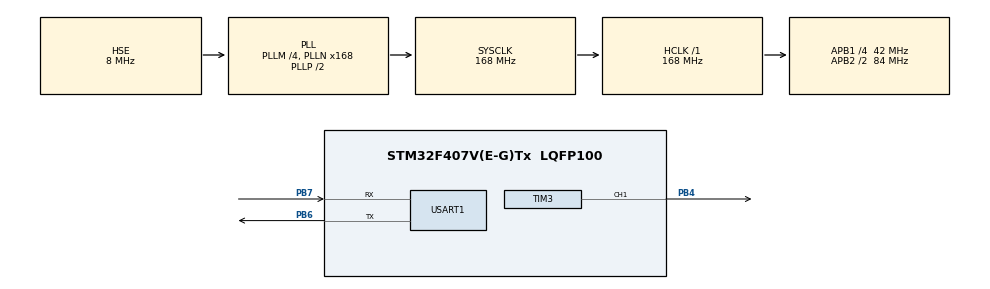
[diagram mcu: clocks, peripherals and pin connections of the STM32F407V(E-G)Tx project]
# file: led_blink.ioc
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FREERTOS.Tasks01=defaultTask,24,128,StartDefaultTask,Default,NULL,Dynamic,NULL,NULL
Mcu.Family=STM32F4
Mcu.Name=STM32F407V(E-G)Tx
Mcu.Package=LQFP100
NVIC.PriorityGroup=NVIC_PRIORITYGROUP_4
NVIC.TIM1_UP_TIM10_IRQn=true\:0\:0\:false\:false\:true\:false\:false\:true
NVIC.TimeBase=TIM1_UP_TIM10_IRQn
NVIC.TimeBaseIP=TIM1
NVIC.USART1_IRQn=true\:5\:0\:false\:false\:true\:true\:true\:true
PA13.Mode=Serial_Wire
PA13.Signal=SYS_JTMS-SWDIO
PA14.Mode=Serial_Wire
PA14.Signal=SYS_JTCK-SWCLK
PB4.Signal=S_TIM3_CH1
PB6.Mode=Asynchronous
PB6.Signal=USART1_TX
PB7.Mode=Asynchronous
PB7.Signal=USART1_RX
PH0-OSC_IN.Mode=HSE-External-Oscillator
PH0-OSC_IN.Signal=RCC_OSC_IN
PH1-OSC_OUT.Mode=HSE-External-Oscillator
PH1-OSC_OUT.Signal=RCC_OSC_OUT
ProjectManager.HeapSize=0x200
ProjectManager.StackSize=0x400
ProjectManager.TargetToolchain=MDK-ARM V5.27
RCC.48MHZClocksFreq_Value=84000000
RCC.AHBFreq_Value=168000000
RCC.APB1CLKDivider=RCC_HCLK_DIV4
RCC.APB1Freq_Value=42000000
RCC.APB1TimFreq_Value=84000000
RCC.APB2CLKDivider=RCC_HCLK_DIV2
RCC.APB2Freq_Value=84000000
RCC.APB2TimFreq_Value=168000000
RCC.CortexFreq_Value=168000000
RCC.HCLKFreq_Value=168000000
RCC.HSE_VALUE=8000000
RCC.HSI_VALUE=16000000
RCC.LSE_VALUE=32768
RCC.PLLM=4
RCC.PLLN=168
RCC.PLLSourceVirtual=RCC_PLLSOURCE_HSE
RCC.SYSCLKFreq_VALUE=168000000
RCC.SYSCLKSource=RCC_SYSCLKSOURCE_PLLCLK
RCC.VCOOutputFreq_Value=336000000
SH.S_TIM3_CH1.0=TIM3_CH1,PWM Generation1 CH1
TIM3.AutoReloadPreload=TIM_AUTORELOAD_PRELOAD_ENABLE
TIM3.Channel-PWM\ Generation1\ CH1=TIM_CHANNEL_1
TIM3.OCMode_PWM-PWM\ Generation1\ CH1=TIM_OCMODE_PWM1
TIM3.Period=999
TIM3.Prescaler=83
USART1.VirtualMode=VM_ASYNC
VP_FREERTOS_VS_CMSIS_V2.Mode=CMSIS_V2
VP_SYS_VS_tim1.Mode=TIM1
VP_TIM3_VS_ClockSourceINT.Mode=Internal
board=custom

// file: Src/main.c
/* USER CODE BEGIN Header */
/**
  ******************************************************************************
  * @file           : main.c
  * @brief          : Main program body
  ******************************************************************************
  * @attention
  *
  * <h2><center>&copy; Copyright (c) 2026 STMicroelectronics.
  * All rights reserved.</center></h2>
  *
  * This software component is licensed by ST under BSD 3-Clause license,
  * the "License"; You may not use this file except in compliance with
  * the License. You may obtain a copy of the License at:
  *                        opensource.org/licenses/BSD-3-Clause
  *
  ******************************************************************************
  */
/* USER CODE END Header */
#include "main.h"
#include "cmsis_os.h"
#include "tim.h"
#include "usart.h"
#include "gpio.h"

/* USER CODE BEGIN Includes */
#include <stdio.h>
/* USER CODE END Includes */

void SystemClock_Config(void);
void MX_FREERTOS_Init(void);

int main(void)
{

  /* MCU Configuration--------------------------------------------------------*/

  /* Reset of all peripherals, Initializes the Flash interface and the Systick. */
  HAL_Init();

  /* Configure the system clock */
  SystemClock_Config();

  /* Initialize all configured peripherals */
  MX_GPIO_Init();
  MX_TIM3_Init();
  MX_USART1_UART_Init();
  /* USER CODE BEGIN 2 */
  Heartbeat_Led_Init();                                /* 初始化板载 LED PB2（心跳灯，任务 C 翻转用） */
  HAL_TIM_PWM_Start(&htim3, TIM_CHANNEL_1);            /* 启动 TIM3 CH1 的 PWM 输出 */
  __HAL_TIM_SET_COMPARE(&htim3, TIM_CHANNEL_1, 500);   /* 固定 50% 占空比：02 里的呼吸 while(1) 已删除（osKernelStart 之后是死代码），任务一会改用 TIM7 中断接管呼吸 */
  printf("Hello STM32F407 HAL!\r\n");
  /* USER CODE END 2 */

  /* Init scheduler */
  osKernelInitialize();  /* Call init function for freertos objects (in freertos.c) */
  MX_FREERTOS_Init();    /* 任务在这里创建（freertos.c 的 USER CODE RTOS_THREADS 区调用了 App_Tasks_Create） */
  /* Start scheduler */
  osKernelStart();

  /* We should never get here as control is now taken by the scheduler */
  /* Infinite loop */
  /* USER CODE BEGIN WHILE */
  /* osKernelStart() 之后调度器接管 CPU，永远不会执行到这里。
   * 02 写的呼吸灯 while(1) 整段删除（死代码）；呼吸逻辑任务一用 TIM7 中断实现。 */
  /* USER CODE END WHILE */

}

void SystemClock_Config(void)
{
  RCC_OscInitTypeDef RCC_OscInitStruct = {0};
  RCC_ClkInitTypeDef RCC_ClkInitStruct = {0};

  /** Configure the main internal regulator output voltage
  */
  __HAL_RCC_PWR_CLK_ENABLE();
  __HAL_PWR_VOLTAGESCALING_CONFIG(PWR_REGULATOR_VOLTAGE_SCALE1);
  /** Initializes the RCC Oscillators according to the specified parameters
  * in the RCC_OscInitTypeDef structure.
  */
  RCC_OscInitStruct.OscillatorType = RCC_OSCILLATORTYPE_HSE;
  RCC_OscInitStruct.HSEState = RCC_HSE_ON;
  RCC_OscInitStruct.PLL.PLLState = RCC_PLL_ON;
  RCC_OscInitStruct.PLL.PLLSource = RCC_PLLSOURCE_HSE;
  RCC_OscInitStruct.PLL.PLLM = 4;
  RCC_OscInitStruct.PLL.PLLN = 168;
  RCC_OscInitStruct.PLL.PLLP = RCC_PLLP_DIV2;
  RCC_OscInitStruct.PLL.PLLQ = 4;
  if (HAL_RCC_OscConfig(&RCC_OscInitStruct) != HAL_OK)
  {
    Error_Handler();
  }
  /** Initializes the CPU, AHB and APB buses clocks
  */
  RCC_ClkInitStruct.ClockType = RCC_CLOCKTYPE_HCLK|RCC_CLOCKTYPE_SYSCLK
                              |RCC_CLOCKTYPE_PCLK1|RCC_CLOCKTYPE_PCLK2;
  RCC_ClkInitStruct.SYSCLKSource = RCC_SYSCLKSOURCE_PLLCLK;
  RCC_ClkInitStruct.AHBCLKDivider = RCC_SYSCLK_DIV1;
  RCC_ClkInitStruct.APB1CLKDivider = RCC_HCLK_DIV4;
  RCC_ClkInitStruct.APB2CLKDivider = RCC_HCLK_DIV2;

  if (HAL_RCC_ClockConfig(&RCC_ClkInitStruct, FLASH_LATENCY_5) != HAL_OK)
  {
    Error_Handler();
  }
}

 /**
  * @brief  Period elapsed callback in non blocking mode
  * @note   This function is called  when TIM1 interrupt took place, inside
  * HAL_TIM_IRQHandler(). It makes a direct call to HAL_IncTick() to increment
  * a global variable "uwTick" used as application time base.
  * @param  htim : TIM handle
  * @retval None
  */
void HAL_TIM_PeriodElapsedCallback(TIM_HandleTypeDef *htim)
{
  if (htim->Instance == TIM1) {
    HAL_IncTick();
  }
}

void Error_Handler(void)
{
  __disable_irq();
  while (1)
  {
  }
}

/************************ (C) COPYRIGHT STMicroelectronics *****END OF FILE****/
